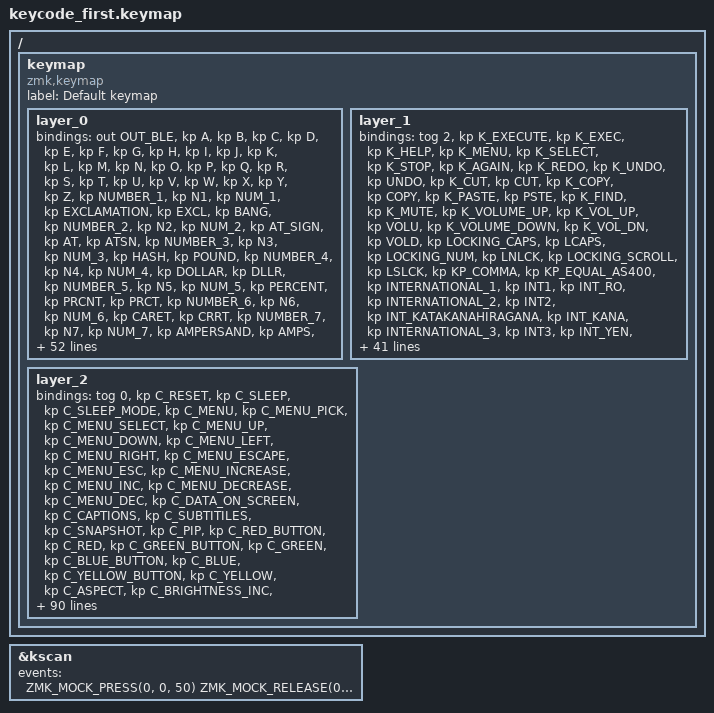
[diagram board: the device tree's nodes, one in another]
#include <dt-bindings/zmk/keys.h>
#include <dt-bindings/zmk/bt.h>
#include <dt-bindings/zmk/outputs.h>
#include <behaviors.dtsi>
#include <dt-bindings/zmk/kscan-mock.h>

/ {
    keymap {
        compatible = "zmk,keymap";
        label = "Default keymap";
        layer_0 {
            bindings = <
                &out OUT_BLE
                &kp A
                &kp B
                &kp C
                &kp D
                &kp E
                &kp F
                &kp G
                &kp H
                &kp I
                &kp J
                &kp K
                &kp L
                &kp M
                &kp N
                &kp O
                &kp P
                &kp Q
                &kp R
                &kp S
                &kp T
                &kp U
                &kp V
                &kp W
                &kp X
                &kp Y
                &kp Z
                &kp NUMBER_1
                &kp N1
                &kp NUM_1
                &kp EXCLAMATION
                &kp EXCL
                &kp BANG
                &kp NUMBER_2
                &kp N2
                &kp NUM_2
                &kp AT_SIGN
                &kp AT
                &kp ATSN
                &kp NUMBER_3
                &kp N3
                &kp NUM_3
                &kp HASH
                &kp POUND
                &kp NUMBER_4
                &kp N4
                &kp NUM_4
                &kp DOLLAR
                &kp DLLR
                &kp NUMBER_5
                &kp N5
                &kp NUM_5
                &kp PERCENT
                &kp PRCNT
                &kp PRCT
                &kp NUMBER_6
                &kp N6
                &kp NUM_6
                &kp CARET
                &kp CRRT
                &kp NUMBER_7
                &kp N7
                &kp NUM_7
                &kp AMPERSAND
                &kp AMPS
                &kp NUMBER_8
                &kp N8
                &kp NUM_8
                &kp ASTERISK
                &kp ASTRK
                &kp STAR
                &kp NUMBER_9
                &kp N9
                &kp NUM_9
                &kp LEFT_PARENTHESIS
                &kp LPAR
                &kp LPRN
                &kp NUMBER_0
                &kp N0
                &kp NUM_0
                &kp RIGHT_PARENTHESIS
                &kp RPAR
                &kp RPRN
                &kp RETURN
                &kp ENTER
                &kp RET
                &kp ESCAPE
                &kp ESC
                &kp BACKSPACE
                &kp BSPC
                &kp BKSP
                &kp TAB
                &kp SPACE
                &kp SPC
                &kp MINUS
                &kp UNDERSCORE
                &kp UNDER
                &kp EQUAL
                &kp EQL
                &kp PLUS
                &kp LEFT_BRACKET
                &kp LBKT
                &kp LEFT_BRACE
                &kp LBRC
                &kp LCUR
                &kp RIGHT_BRACKET
                &kp RBKT
                &kp RIGHT_BRACE
                &kp RBRC
                &kp RCUR
                &kp BACKSLASH
                &kp BSLH
                &kp PIPE
                &kp NON_US_HASH
                &kp TILDE2
                &kp SEMICOLON
                &kp SEMI
                &kp SCLN
                &kp COLON
                &kp COLN
                &kp SINGLE_QUOTE
                &kp SQT
                &kp APOSTROPHE
                &kp APOS
                &kp QUOT
                &kp DOUBLE_QUOTES
                &kp DQT
                &kp GRAVE
                &kp GRAV
                &kp TILDE
                &kp TILD
                &kp COMMA
                &kp CMMA
                &kp LESS_THAN
                &kp LT
                &kp LABT
                &kp PERIOD
                &kp DOT
                &kp GREATER_THAN
                &kp GT
                &kp RABT
                &kp SLASH
                &kp FSLH
                &kp QUESTION
                &kp QMARK
                &kp CAPSLOCK
                &kp CAPS
                &kp CLCK
                &kp F1
                &kp F2
                &kp F3
                &kp F4
                &kp F5
                &kp F6
                &kp F7
                &kp F8
                &kp F9
                &kp F10
                &kp F11
                &kp F12
                &kp PRINTSCREEN
                &kp PSCRN
                &kp PRSC
                &kp SCROLLLOCK
                &kp SLCK
                &kp SCLK
                &kp PAUSE_BREAK
                &kp PAUS
                &kp INSERT
                &kp INS
                &kp HOME
                &kp PAGE_UP
                &kp PG_UP
                &kp PGUP
                &kp DELETE
                &kp DEL
                &kp END
                &kp PAGE_DOWN
                &kp PG_DN
                &kp PGDN
                &kp RIGHT_ARROW
                &kp RIGHT
                &kp RARW
                &kp LEFT_ARROW
                &kp LEFT
                &kp LARW
                &kp DOWN_ARROW
                &kp DOWN
                &kp DARW
                &kp UP_ARROW
                &kp UP
                &kp UARW
                &kp KP_NUMLOCK
                &kp KP_NUM
                &kp KP_NLCK
                &kp CLEAR2
                &kp KP_DIVIDE
                &kp KP_SLASH
                &kp KDIV
                &kp KP_MULTIPLY
                &kp KP_ASTERISK
                &kp KMLT
                &kp KP_MINUS
                &kp KP_SUBTRACT
                &kp KMIN
                &kp KP_PLUS
                &kp KPLS
                &kp KP_ENTER
                &kp KP_NUMBER_1
                &kp KP_N1
                &kp KP_NUMBER_2
                &kp KP_N2
                &kp KP_NUMBER_3
                &kp KP_N3
                &kp KP_NUMBER_4
                &kp KP_N4
                &kp KP_NUMBER_5
                &kp KP_N5
                &kp KP_NUMBER_6
                &kp KP_N6
                &kp KP_NUMBER_7
                &kp KP_N7
                &kp KP_NUMBER_8
                &kp KP_N8
                &kp KP_NUMBER_9
                &kp KP_N9
                &kp KP_NUMBER_0
                &kp KP_N0
                &kp KP_DOT
                &kp NON_US_BACKSLASH
                &kp NON_US_BSLH
                &kp PIPE2
                &kp K_APPLICATION
                &kp K_POWER
                &kp K_APP
                &kp K_CONTEXT_MENU
                &kp K_CMENU
                &kp GUI
                &kp KP_EQUAL
                &kp F13
                &kp F14
                &kp F15
                &kp F16
                &kp F17
                &kp F18
                &kp F19
                &kp F20
                &kp F21
                &kp F22
                &kp F23
                &kp F24
            >;
        };
        layer_1 {
            bindings = <
                &tog 2
                &kp K_EXECUTE
                &kp K_EXEC
                &kp K_HELP
                &kp K_MENU
                &kp K_SELECT
                &kp K_STOP
                &kp K_AGAIN
                &kp K_REDO
                &kp K_UNDO
                &kp UNDO
                &kp K_CUT
                &kp CUT
                &kp K_COPY
                &kp COPY
                &kp K_PASTE
                &kp PSTE
                &kp K_FIND
                &kp K_MUTE
                &kp K_VOLUME_UP
                &kp K_VOL_UP
                &kp VOLU
                &kp K_VOLUME_DOWN
                &kp K_VOL_DN
                &kp VOLD
                &kp LOCKING_CAPS
                &kp LCAPS
                &kp LOCKING_NUM
                &kp LNLCK
                &kp LOCKING_SCROLL
                &kp LSLCK
                &kp KP_COMMA
                &kp KP_EQUAL_AS400
                &kp INTERNATIONAL_1
                &kp INT1
                &kp INT_RO
                &kp INTERNATIONAL_2
                &kp INT2
                &kp INT_KATAKANAHIRAGANA
                &kp INT_KANA
                &kp INTERNATIONAL_3
                &kp INT3
                &kp INT_YEN
                &kp INTERNATIONAL_4
                &kp INT4
                &kp INT_HENKAN
                &kp INTERNATIONAL_5
                &kp INT5
                &kp INT_MUHENKAN
                &kp INTERNATIONAL_6
                &kp INT6
                &kp INT_KPJPCOMMA
                &kp INTERNATIONAL_7
                &kp INT7
                &kp INTERNATIONAL_8
                &kp INT8
                &kp INTERNATIONAL_9
                &kp INT9
                &kp LANGUAGE_1
                &kp LANG1
                &kp LANG_HANGEUL
                &kp LANGUAGE_2
                &kp LANG2
                &kp LANG_HANJA
                &kp LANGUAGE_3
                &kp LANG3
                &kp LANG_KATAKANA
                &kp LANGUAGE_4
                &kp LANG4
                &kp LANG_HIRAGANA
                &kp LANGUAGE_5
                &kp LANG5
                &kp LANG_ZENKAKUHANKAKU
                &kp LANGUAGE_6
                &kp LANG6
                &kp LANGUAGE_7
                &kp LANG7
                &kp LANGUAGE_8
                &kp LANG8
                &kp LANGUAGE_9
                &kp LANG9
                &kp ALT_ERASE
                &kp SYSREQ
                &kp ATTENTION
                &kp K_CANCEL
                &kp CLEAR
                &kp PRIOR
                &kp RETURN2
                &kp RET2
                &kp SEPARATOR
                &kp OUT
                &kp OPER
                &kp CLEAR_AGAIN
                &kp CRSEL
                &kp EXSEL
                &kp CURU
                &kp KP_LEFT_PARENTHESIS
                &kp KP_LPAR
                &kp KP_RIGHT_PARENTHESIS
                &kp KP_RPAR
                &kp KSPC
                &kp KP_CLEAR
                &kp LEFT_CONTROL
                &kp LCTRL
                &kp LCTL
                &kp LEFT_SHIFT
                &kp LSHFT
                &kp LSFT
                &kp LEFT_ALT
                &kp LALT
                &kp LEFT_GUI
                &kp LGUI
                &kp LEFT_WIN
                &kp LWIN
                &kp LEFT_COMMAND
                &kp LCMD
                &kp LEFT_META
                &kp LMETA
                &kp RIGHT_CONTROL
                &kp RCTRL
                &kp RCTL
                &kp RIGHT_SHIFT
                &kp RSHFT
                &kp RSFT
                &kp RIGHT_ALT
                &kp RALT
                &kp RIGHT_GUI
                &kp RGUI
                &kp RIGHT_WIN
                &kp RWIN
                &kp RIGHT_COMMAND
                &kp RCMD
                &kp RIGHT_META
                &kp RMETA
                &kp K_PLAY_PAUSE
                &kp K_PP
                &kp K_STOP2
                &kp K_PREVIOUS
                &kp K_PREV
                &kp K_NEXT
                &kp K_EJECT
                &kp K_VOLUME_UP2
                &kp K_VOL_UP2
                &kp K_VOLUME_DOWN2
                &kp K_VOL_DN2
                &kp K_MUTE2
                &kp K_WWW
                &kp K_BACK
                &kp K_FORWARD
                &kp K_STOP3
                &kp K_FIND2
                &kp K_SCROLL_UP
                &kp K_SCROLL_DOWN
                &kp K_EDIT
                &kp K_SLEEP
                &kp K_LOCK
                &kp K_SCREENSAVER
                &kp K_COFFEE
                &kp K_REFRESH
                &kp K_CALCULATOR
                &kp K_CALC
            >;
        };
        layer_2 {
            bindings = <
                &tog 0
                &kp C_RESET
                &kp C_SLEEP
                &kp C_SLEEP_MODE
                &kp C_MENU
                &kp C_MENU_PICK
                &kp C_MENU_SELECT
                &kp C_MENU_UP
                &kp C_MENU_DOWN
                &kp C_MENU_LEFT
                &kp C_MENU_RIGHT
                &kp C_MENU_ESCAPE
                &kp C_MENU_ESC
                &kp C_MENU_INCREASE
                &kp C_MENU_INC
                &kp C_MENU_DECREASE
                &kp C_MENU_DEC
                &kp C_DATA_ON_SCREEN
                &kp C_CAPTIONS
                &kp C_SUBTITILES
                &kp C_SNAPSHOT
                &kp C_PIP
                &kp C_RED_BUTTON
                &kp C_RED
                &kp C_GREEN_BUTTON
                &kp C_GREEN
                &kp C_BLUE_BUTTON
                &kp C_BLUE
                &kp C_YELLOW_BUTTON
                &kp C_YELLOW
                &kp C_ASPECT
                &kp C_BRIGHTNESS_INC
                &kp C_BRI_INC
                &kp C_BRI_UP
                &kp C_BRIGHTNESS_DEC
                &kp C_BRI_DEC
                &kp C_BRI_DN
                &kp C_BACKLIGHT_TOGGLE
                &kp C_BKLT_TOG
                &kp C_BRIGHTNESS_MINIMUM
                &kp C_BRI_MIN
                &kp C_BRIGHTNESS_MAXIMUM
                &kp C_BRI_MAX
                &kp C_BRIGHTNESS_AUTO
                &kp C_BRI_AUTO
                &kp C_MEDIA_STEP
                &kp C_MODE_STEP
                &kp C_RECALL_LAST
                &kp C_CHAN_LAST
                &kp C_MEDIA_COMPUTER
                &kp C_MEDIA_TV
                &kp C_MEDIA_WWW
                &kp C_MEDIA_DVD
                &kp C_MEDIA_PHONE
                &kp C_MEDIA_GUIDE
                &kp C_MEDIA_VIDEOPHONE
                &kp C_MEDIA_GAMES
                &kp C_MEDIA_MESSAGES
                &kp C_MEDIA_CD
                &kp C_MEDIA_VCR
                &kp C_MEDIA_TUNER
                &kp C_QUIT
                &kp C_HELP
                &kp C_MEDIA_TAPE
                &kp C_MEDIA_CABLE
                &kp C_MEDIA_SATELLITE
                &kp C_MEDIA_HOME
                &kp C_CHANNEL_INC
                &kp C_CHAN_INC
                &kp C_CHANNEL_DEC
                &kp C_CHAN_DEC
                &kp C_MEDIA_VCR_PLUS
                &kp C_PLAY
                &kp C_PAUSE
                &kp C_RECORD
                &kp C_REC
                &kp C_FAST_FORWARD
                &kp C_FF
                &kp C_REWIND
                &kp C_RW
                &kp C_NEXT
                &kp M_NEXT
                &kp C_PREVIOUS
                &kp C_PREV
                &kp M_PREV
                &kp C_STOP
                &kp M_STOP
                &kp C_EJECT
                &kp M_EJCT
                &kp C_RANDOM_PLAY
                &kp C_SHUFFLE
                &kp C_REPEAT
                &kp C_SLOW_TRACKING
                &kp C_SLOW2
                &kp C_STOP_EJECT
                &kp C_PLAY_PAUSE
                &kp C_PP
                &kp M_PLAY
                &kp C_VOICE_COMMAND
                &kp C_MUTE
                &kp M_MUTE
                &kp C_BASS_BOOST
                &kp C_VOLUME_UP
                &kp C_VOL_UP
                &kp M_VOLU
                &kp C_VOLUME_DOWN
                &kp C_VOL_DN
                &kp M_VOLD
                &kp C_SLOW
                &kp C_ALTERNATE_AUDIO_INCREMENT
                &kp C_ALT_AUDIO_INC
                &kp C_AL_CCC
                &kp C_AL_WORD
                &kp C_AL_TEXT_EDITOR
                &kp C_AL_SPREADSHEET
                &kp C_AL_SHEET
                &kp C_AL_GRAPHICS_EDITOR
                &kp C_AL_PRESENTATION
                &kp C_AL_DATABASE
                &kp C_AL_DB
                &kp C_AL_EMAIL
                &kp C_AL_MAIL
                &kp C_AL_NEWS
                &kp C_AL_VOICEMAIL
                &kp C_AL_CONTACTS
                &kp C_AL_ADDRESS_BOOK
                &kp C_AL_CALENDAR
                &kp C_AL_CAL
                &kp C_AL_TASK_MANAGER
                &kp C_AL_JOURNAL
                &kp C_AL_FINANCE
                &kp C_AL_CALCULATOR
                &kp C_AL_CALC
                &kp C_AL_AV_CAPTURE_PLAYBACK
                &kp C_AL_MY_COMPUTER
                &kp C_AL_WWW
                &kp C_AL_NETWORK_CHAT
                &kp C_AL_CHAT
                &kp C_AL_LOGOFF
                &kp C_AL_LOCK
                &kp C_AL_SCREENSAVER
                &kp C_AL_COFFEE
                &kp C_AL_CONTROL_PANEL
                &kp C_AL_SELECT_TASK
                &kp C_AL_NEXT_TASK
                &kp C_AL_PREVIOUS_TASK
                &kp C_AL_PREV_TASK
                &kp C_AL_HELP
                &kp C_AL_DOCUMENTS
                &kp C_AL_DOCS
                &kp C_AL_SPELLCHECK
                &kp C_AL_SPELL
                &kp C_AL_KEYBOARD_LAYOUT
                &kp C_AL_SCREEN_SAVER
                &kp C_AL_FILE_BROWSER
                &kp C_AL_FILES
                &kp C_AL_IMAGE_BROWSER
                &kp C_AL_IMAGES
                &kp C_AL_AUDIO_BROWSER
                &kp C_AL_AUDIO
                &kp C_AL_MUSIC
                &kp C_AL_MOVIE_BROWSER
                &kp C_AL_MOVIES
                &kp C_AL_INSTANT_MESSAGING
                &kp C_AL_IM
                &kp C_AL_OEM_FEATURES
                &kp C_AL_TIPS
                &kp C_AL_TUTORIAL
                &kp C_AC_NEW
                &kp C_AC_OPEN
                &kp C_AC_CLOSE
                &kp C_AC_EXIT
                &kp C_AC_SAVE
                &kp C_AC_PRINT
                &kp C_AC_PROPERTIES
                &kp C_AC_PROPS
                &kp C_AC_UNDO
                &kp C_AC_COPY
                &kp C_AC_CUT
                &kp C_AC_PASTE
                &kp C_AC_FIND
                &kp C_AC_SEARCH
                &kp C_AC_GOTO
                &kp C_AC_HOME
                &kp C_AC_BACK
                &kp C_AC_FORWARD
                &kp C_AC_STOP
                &kp C_AC_REFRESH
                &kp C_AC_BOOKMARKS
                &kp C_AC_FAVORITES
                &kp C_AC_FAVOURITES
                &kp C_AC_ZOOM_IN
                &kp C_AC_ZOOM_OUT
                &kp C_AC_ZOOM
                &kp C_AC_VIEW_TOGGLE
                &kp C_AC_SCROLL_UP
                &kp C_AC_SCROLL_DOWN
                &kp C_AC_EDIT
                &kp C_AC_CANCEL
                &kp C_AC_INSERT
                &kp C_AC_INS
                &kp C_AC_DEL
                &kp C_AC_REDO
                &kp C_AC_REPLY
                &kp C_AC_FORWARD_MAIL
                &kp C_AC_SEND
                &kp C_AC_DESKTOP_SHOW_ALL_WINDOWS
                &kp C_KEYBOARD_INPUT_ASSIST_PREVIOUS
                &kp C_KBIA_PREV
                &kp C_KEYBOARD_INPUT_ASSIST_NEXT
                &kp C_KBIA_NEXT
                &kp C_KEYBOARD_INPUT_ASSIST_PREVIOUS_GROUP
                &kp C_KBIA_PREV_GRP
                &kp C_KEYBOARD_INPUT_ASSIST_NEXT_GROUP
                &kp C_KBIA_NEXT_GRP
                &kp C_KEYBOARD_INPUT_ASSIST_ACCEPT
                &kp C_KBIA_ACCEPT
                &kp C_KEYBOARD_INPUT_ASSIST_CANCEL
                &kp C_KBIA_CANCEL
            >;
        };
    };
};

&kscan {
    events = < 
        ZMK_MOCK_PRESS(0, 0, 50)
        ZMK_MOCK_RELEASE(0, 0, 10000)
        ZMK_MOCK_PRESS(1, 0, 50)
        ZMK_MOCK_RELEASE(1, 0, 100)
        ZMK_MOCK_PRESS(1, 0, 50)
        ZMK_MOCK_RELEASE(1, 0, 100)
        ZMK_MOCK_PRESS(2, 0, 50)
        ZMK_MOCK_RELEASE(2, 0, 100)
        ZMK_MOCK_PRESS(3, 0, 50)
        ZMK_MOCK_RELEASE(3, 0, 100)
        ZMK_MOCK_PRESS(4, 0, 50)
        ZMK_MOCK_RELEASE(4, 0, 100)
        ZMK_MOCK_PRESS(5, 0, 50)
        ZMK_MOCK_RELEASE(5, 0, 100)
        ZMK_MOCK_PRESS(6, 0, 50)
        ZMK_MOCK_RELEASE(6, 0, 100)
        ZMK_MOCK_PRESS(7, 0, 50)
        ZMK_MOCK_RELEASE(7, 0, 100)
        ZMK_MOCK_PRESS(8, 0, 50)
        ZMK_MOCK_RELEASE(8, 0, 100)
        ZMK_MOCK_PRESS(9, 0, 50)
        ZMK_MOCK_RELEASE(9, 0, 100)
        ZMK_MOCK_PRESS(10, 0, 50)
        ZMK_MOCK_RELEASE(10, 0, 100)
        ZMK_MOCK_PRESS(11, 0, 50)
        ZMK_MOCK_RELEASE(11, 0, 100)
        ZMK_MOCK_PRESS(12, 0, 50)
        ZMK_MOCK_RELEASE(12, 0, 100)
        ZMK_MOCK_PRESS(13, 0, 50)
        ZMK_MOCK_RELEASE(13, 0, 100)
        ZMK_MOCK_PRESS(14, 0, 50)
        ZMK_MOCK_RELEASE(14, 0, 100)
        ZMK_MOCK_PRESS(15, 0, 50)
        ZMK_MOCK_RELEASE(15, 0, 100)
        ZMK_MOCK_PRESS(16, 0, 50)
        ZMK_MOCK_RELEASE(16, 0, 100)
        ZMK_MOCK_PRESS(17, 0, 50)
        ZMK_MOCK_RELEASE(17, 0, 100)
        ZMK_MOCK_PRESS(18, 0, 50)
        ZMK_MOCK_RELEASE(18, 0, 100)
        ZMK_MOCK_PRESS(19, 0, 50)
        ZMK_MOCK_RELEASE(19, 0, 100)
        ZMK_MOCK_PRESS(20, 0, 50)
        ZMK_MOCK_RELEASE(20, 0, 100)
        ZMK_MOCK_PRESS(21, 0, 50)
        ZMK_MOCK_RELEASE(21, 0, 100)
        ZMK_MOCK_PRESS(22, 0, 50)
        ZMK_MOCK_RELEASE(22, 0, 100)
        ZMK_MOCK_PRESS(23, 0, 50)
        ZMK_MOCK_RELEASE(23, 0, 100)
        ZMK_MOCK_PRESS(24, 0, 50)
        ZMK_MOCK_RELEASE(24, 0, 100)
        ZMK_MOCK_PRESS(25, 0, 50)
        ZMK_MOCK_RELEASE(25, 0, 100)
        ZMK_MOCK_PRESS(26, 0, 50)
        ZMK_MOCK_RELEASE(26, 0, 100)
        ZMK_MOCK_PRESS(27, 0, 50)
        ZMK_MOCK_RELEASE(27, 0, 100)
        ZMK_MOCK_PRESS(28, 0, 50)
        ZMK_MOCK_RELEASE(28, 0, 100)
        ZMK_MOCK_PRESS(29, 0, 50)
        ZMK_MOCK_RELEASE(29, 0, 100)
        ZMK_MOCK_PRESS(30, 0, 50)
        ZMK_MOCK_RELEASE(30, 0, 100)
        ZMK_MOCK_PRESS(31, 0, 50)
        ZMK_MOCK_RELEASE(31, 0, 100)
        ZMK_MOCK_PRESS(32, 0, 50)
        ZMK_MOCK_RELEASE(32, 0, 100)
        ZMK_MOCK_PRESS(33, 0, 50)
        ZMK_MOCK_RELEASE(33, 0, 100)
        ZMK_MOCK_PRESS(34, 0, 50)
        ZMK_MOCK_RELEASE(34, 0, 100)
        ZMK_MOCK_PRESS(35, 0, 50)
        ZMK_MOCK_RELEASE(35, 0, 100)
        ZMK_MOCK_PRESS(36, 0, 50)
        ZMK_MOCK_RELEASE(36, 0, 100)
        ZMK_MOCK_PRESS(37, 0, 50)
        ZMK_MOCK_RELEASE(37, 0, 100)
        ZMK_MOCK_PRESS(38, 0, 50)
        ZMK_MOCK_RELEASE(38, 0, 100)
        ZMK_MOCK_PRESS(39, 0, 50)
        ZMK_MOCK_RELEASE(39, 0, 100)
        ZMK_MOCK_PRESS(40, 0, 50)
        ZMK_MOCK_RELEASE(40, 0, 100)
        ZMK_MOCK_PRESS(41, 0, 50)
        ZMK_MOCK_RELEASE(41, 0, 100)
        ZMK_MOCK_PRESS(42, 0, 50)
        ZMK_MOCK_RELEASE(42, 0, 100)
        ZMK_MOCK_PRESS(43, 0, 50)
        ZMK_MOCK_RELEASE(43, 0, 100)
        ZMK_MOCK_PRESS(44, 0, 50)
        ZMK_MOCK_RELEASE(44, 0, 100)
        ZMK_MOCK_PRESS(45, 0, 50)
        ZMK_MOCK_RELEASE(45, 0, 100)
        ZMK_MOCK_PRESS(46, 0, 50)
        ZMK_MOCK_RELEASE(46, 0, 100)
        ZMK_MOCK_PRESS(47, 0, 50)
        ZMK_MOCK_RELEASE(47, 0, 100)
        ZMK_MOCK_PRESS(48, 0, 50)
        ZMK_MOCK_RELEASE(48, 0, 100)
        ZMK_MOCK_PRESS(49, 0, 50)
        ZMK_MOCK_RELEASE(49, 0, 100)
        ZMK_MOCK_PRESS(50, 0, 50)
        ZMK_MOCK_RELEASE(50, 0, 100)
        ZMK_MOCK_PRESS(51, 0, 50)
        ZMK_MOCK_RELEASE(51, 0, 100)
        ZMK_MOCK_PRESS(52, 0, 50)
        ZMK_MOCK_RELEASE(52, 0, 100)
        ZMK_MOCK_PRESS(53, 0, 50)
        ZMK_MOCK_RELEASE(53, 0, 100)
        ZMK_MOCK_PRESS(54, 0, 50)
        ZMK_MOCK_RELEASE(54, 0, 100)
        ZMK_MOCK_PRESS(55, 0, 50)
        ZMK_MOCK_RELEASE(55, 0, 100)
        ZMK_MOCK_PRESS(56, 0, 50)
        ZMK_MOCK_RELEASE(56, 0, 100)
        ZMK_MOCK_PRESS(57, 0, 50)
        ZMK_MOCK_RELEASE(57, 0, 100)
        ZMK_MOCK_PRESS(58, 0, 50)
        ZMK_MOCK_RELEASE(58, 0, 100)
        ZMK_MOCK_PRESS(59, 0, 50)
        ZMK_MOCK_RELEASE(59, 0, 100)
        ZMK_MOCK_PRESS(60, 0, 50)
        ZMK_MOCK_RELEASE(60, 0, 100)
        ZMK_MOCK_PRESS(61, 0, 50)
        ZMK_MOCK_RELEASE(61, 0, 100)
        ZMK_MOCK_PRESS(62, 0, 50)
        ZMK_MOCK_RELEASE(62, 0, 100)
        ZMK_MOCK_PRESS(63, 0, 50)
        ZMK_MOCK_RELEASE(63, 0, 100)
        ZMK_MOCK_PRESS(64, 0, 50)
        ZMK_MOCK_RELEASE(64, 0, 100)
        ZMK_MOCK_PRESS(65, 0, 50)
        ZMK_MOCK_RELEASE(65, 0, 100)
        ZMK_MOCK_PRESS(66, 0, 50)
        ZMK_MOCK_RELEASE(66, 0, 100)
        ZMK_MOCK_PRESS(67, 0, 50)
        ZMK_MOCK_RELEASE(67, 0, 100)
        ZMK_MOCK_PRESS(68, 0, 50)
        ZMK_MOCK_RELEASE(68, 0, 100)
        ZMK_MOCK_PRESS(69, 0, 50)
        ZMK_MOCK_RELEASE(69, 0, 100)
        ZMK_MOCK_PRESS(70, 0, 50)
        ZMK_MOCK_RELEASE(70, 0, 100)
        ZMK_MOCK_PRESS(71, 0, 50)
        ZMK_MOCK_RELEASE(71, 0, 100)
        ZMK_MOCK_PRESS(72, 0, 50)
        ZMK_MOCK_RELEASE(72, 0, 100)
        ZMK_MOCK_PRESS(73, 0, 50)
        ZMK_MOCK_RELEASE(73, 0, 100)
        ZMK_MOCK_PRESS(74, 0, 50)
        ZMK_MOCK_RELEASE(74, 0, 100)
        ZMK_MOCK_PRESS(75, 0, 50)
        ZMK_MOCK_RELEASE(75, 0, 100)
        ZMK_MOCK_PRESS(76, 0, 50)
        ZMK_MOCK_RELEASE(76, 0, 100)
        ZMK_MOCK_PRESS(77, 0, 50)
        ZMK_MOCK_RELEASE(77, 0, 100)
        ZMK_MOCK_PRESS(78, 0, 50)
        ZMK_MOCK_RELEASE(78, 0, 100)
        ZMK_MOCK_PRESS(79, 0, 50)
        ZMK_MOCK_RELEASE(79, 0, 100)
        ZMK_MOCK_PRESS(80, 0, 50)
        ZMK_MOCK_RELEASE(80, 0, 100)
        ZMK_MOCK_PRESS(81, 0, 50)
        ZMK_MOCK_RELEASE(81, 0, 100)
        ZMK_MOCK_PRESS(82, 0, 50)
        ZMK_MOCK_RELEASE(82, 0, 100)
        ZMK_MOCK_PRESS(83, 0, 50)
        ZMK_MOCK_RELEASE(83, 0, 100)
        ZMK_MOCK_PRESS(84, 0, 50)
        ZMK_MOCK_RELEASE(84, 0, 100)
        ZMK_MOCK_PRESS(85, 0, 50)
        ZMK_MOCK_RELEASE(85, 0, 100)
        ZMK_MOCK_PRESS(86, 0, 50)
        ZMK_MOCK_RELEASE(86, 0, 100)
        ZMK_MOCK_PRESS(87, 0, 50)
        ZMK_MOCK_RELEASE(87, 0, 100)
        ZMK_MOCK_PRESS(88, 0, 50)
        ZMK_MOCK_RELEASE(88, 0, 100)
        ZMK_MOCK_PRESS(89, 0, 50)
        ZMK_MOCK_RELEASE(89, 0, 100)
        ZMK_MOCK_PRESS(90, 0, 50)
        ZMK_MOCK_RELEASE(90, 0, 100)
        ZMK_MOCK_PRESS(91, 0, 50)
        ZMK_MOCK_RELEASE(91, 0, 100)
        ZMK_MOCK_PRESS(92, 0, 50)
        ZMK_MOCK_RELEASE(92, 0, 100)
        ZMK_MOCK_PRESS(93, 0, 50)
        ZMK_MOCK_RELEASE(93, 0, 100)
        ZMK_MOCK_PRESS(94, 0, 50)
        ZMK_MOCK_RELEASE(94, 0, 100)
        ZMK_MOCK_PRESS(95, 0, 50)
        ZMK_MOCK_RELEASE(95, 0, 100)
        ZMK_MOCK_PRESS(96, 0, 50)
        ZMK_MOCK_RELEASE(96, 0, 100)
        ZMK_MOCK_PRESS(97, 0, 50)
        ZMK_MOCK_RELEASE(97, 0, 100)
        ZMK_MOCK_PRESS(98, 0, 50)
        ZMK_MOCK_RELEASE(98, 0, 100)
        ZMK_MOCK_PRESS(99, 0, 50)
        ZMK_MOCK_RELEASE(99, 0, 100)
        ZMK_MOCK_PRESS(100, 0, 50)
        ZMK_MOCK_RELEASE(100, 0, 100)
        ZMK_MOCK_PRESS(101, 0, 50)
        ZMK_MOCK_RELEASE(101, 0, 100)
        ZMK_MOCK_PRESS(102, 0, 50)
        ZMK_MOCK_RELEASE(102, 0, 100)
        ZMK_MOCK_PRESS(103, 0, 50)
        ZMK_MOCK_RELEASE(103, 0, 100)
        ZMK_MOCK_PRESS(104, 0, 50)
        ZMK_MOCK_RELEASE(104, 0, 100)
        ZMK_MOCK_PRESS(105, 0, 50)
        ZMK_MOCK_RELEASE(105, 0, 100)
        ZMK_MOCK_PRESS(106, 0, 50)
        ZMK_MOCK_RELEASE(106, 0, 100)
        ZMK_MOCK_PRESS(107, 0, 50)
        ZMK_MOCK_RELEASE(107, 0, 100)
        ZMK_MOCK_PRESS(108, 0, 50)
        ZMK_MOCK_RELEASE(108, 0, 100)
        ZMK_MOCK_PRESS(109, 0, 50)
        ZMK_MOCK_RELEASE(109, 0, 100)
        ZMK_MOCK_PRESS(110, 0, 50)
        ZMK_MOCK_RELEASE(110, 0, 100)
        ZMK_MOCK_PRESS(111, 0, 50)
        ZMK_MOCK_RELEASE(111, 0, 100)
        ZMK_MOCK_PRESS(112, 0, 50)
        ZMK_MOCK_RELEASE(112, 0, 100)
        ZMK_MOCK_PRESS(113, 0, 50)
        ZMK_MOCK_RELEASE(113, 0, 100)
        ZMK_MOCK_PRESS(114, 0, 50)
        ZMK_MOCK_RELEASE(114, 0, 100)
        ZMK_MOCK_PRESS(115, 0, 50)
        ZMK_MOCK_RELEASE(115, 0, 100)
        ZMK_MOCK_PRESS(116, 0, 50)
        ZMK_MOCK_RELEASE(116, 0, 100)
        ZMK_MOCK_PRESS(117, 0, 50)
        ZMK_MOCK_RELEASE(117, 0, 100)
        ZMK_MOCK_PRESS(118, 0, 50)
        ZMK_MOCK_RELEASE(118, 0, 100)
        ZMK_MOCK_PRESS(119, 0, 50)
        ZMK_MOCK_RELEASE(119, 0, 100)
        ZMK_MOCK_PRESS(120, 0, 50)
        ZMK_MOCK_RELEASE(120, 0, 100)
        ZMK_MOCK_PRESS(121, 0, 50)
        ZMK_MOCK_RELEASE(121, 0, 100)
        ZMK_MOCK_PRESS(122, 0, 50)
        ZMK_MOCK_RELEASE(122, 0, 100)
        ZMK_MOCK_PRESS(123, 0, 50)
        ZMK_MOCK_RELEASE(123, 0, 100)
        ZMK_MOCK_PRESS(124, 0, 50)
        ZMK_MOCK_RELEASE(124, 0, 100)
        ZMK_MOCK_PRESS(125, 0, 50)
        ZMK_MOCK_RELEASE(125, 0, 100)
        ZMK_MOCK_PRESS(126, 0, 50)
        ZMK_MOCK_RELEASE(126, 0, 100)
        ZMK_MOCK_PRESS(127, 0, 50)
        ZMK_MOCK_RELEASE(127, 0, 100)
        ZMK_MOCK_PRESS(128, 0, 50)
        ZMK_MOCK_RELEASE(128, 0, 100)
        ZMK_MOCK_PRESS(129, 0, 50)
        ZMK_MOCK_RELEASE(129, 0, 100)
        ZMK_MOCK_PRESS(130, 0, 50)
        ZMK_MOCK_RELEASE(130, 0, 100)
        ZMK_MOCK_PRESS(131, 0, 50)
        ZMK_MOCK_RELEASE(131, 0, 100)
        ZMK_MOCK_PRESS(132, 0, 50)
        ZMK_MOCK_RELEASE(132, 0, 100)
        ZMK_MOCK_PRESS(133, 0, 50)
        ZMK_MOCK_RELEASE(133, 0, 100)
        ZMK_MOCK_PRESS(134, 0, 50)
        ZMK_MOCK_RELEASE(134, 0, 100)
        ZMK_MOCK_PRESS(135, 0, 50)
        ZMK_MOCK_RELEASE(135, 0, 100)
        ZMK_MOCK_PRESS(136, 0, 50)
        ZMK_MOCK_RELEASE(136, 0, 100)
        ZMK_MOCK_PRESS(137, 0, 50)
        ZMK_MOCK_RELEASE(137, 0, 100)
        ZMK_MOCK_PRESS(138, 0, 50)
        ZMK_MOCK_RELEASE(138, 0, 100)
        ZMK_MOCK_PRESS(139, 0, 50)
        ZMK_MOCK_RELEASE(139, 0, 100)
        ZMK_MOCK_PRESS(140, 0, 50)
        ZMK_MOCK_RELEASE(140, 0, 100)
        ZMK_MOCK_PRESS(141, 0, 50)
        ZMK_MOCK_RELEASE(141, 0, 100)
        ZMK_MOCK_PRESS(142, 0, 50)
        ZMK_MOCK_RELEASE(142, 0, 100)
        ZMK_MOCK_PRESS(143, 0, 50)
        ZMK_MOCK_RELEASE(143, 0, 100)
        ZMK_MOCK_PRESS(144, 0, 50)
        ZMK_MOCK_RELEASE(144, 0, 100)
        ZMK_MOCK_PRESS(145, 0, 50)
        ZMK_MOCK_RELEASE(145, 0, 100)
        ZMK_MOCK_PRESS(146, 0, 50)
        ZMK_MOCK_RELEASE(146, 0, 100)
        ZMK_MOCK_PRESS(147, 0, 50)
        ZMK_MOCK_RELEASE(147, 0, 100)
        ZMK_MOCK_PRESS(148, 0, 50)
        ZMK_MOCK_RELEASE(148, 0, 100)
        ZMK_MOCK_PRESS(149, 0, 50)
        ZMK_MOCK_RELEASE(149, 0, 100)
        ZMK_MOCK_PRESS(150, 0, 50)
        ZMK_MOCK_RELEASE(150, 0, 100)
        ZMK_MOCK_PRESS(151, 0, 50)
        ZMK_MOCK_RELEASE(151, 0, 100)
        ZMK_MOCK_PRESS(152, 0, 50)
        ZMK_MOCK_RELEASE(152, 0, 100)
        ZMK_MOCK_PRESS(153, 0, 50)
        ZMK_MOCK_RELEASE(153, 0, 100)
        ZMK_MOCK_PRESS(154, 0, 50)
        ZMK_MOCK_RELEASE(154, 0, 100)
        ZMK_MOCK_PRESS(155, 0, 50)
        ZMK_MOCK_RELEASE(155, 0, 100)
        ZMK_MOCK_PRESS(156, 0, 50)
        ZMK_MOCK_RELEASE(156, 0, 100)
        ZMK_MOCK_PRESS(157, 0, 50)
        ZMK_MOCK_RELEASE(157, 0, 100)
        ZMK_MOCK_PRESS(158, 0, 50)
        ZMK_MOCK_RELEASE(158, 0, 100)
        ZMK_MOCK_PRESS(159, 0, 50)
        ZMK_MOCK_RELEASE(159, 0, 100)
        ZMK_MOCK_PRESS(160, 0, 50)
        ZMK_MOCK_RELEASE(160, 0, 100)
        ZMK_MOCK_PRESS(161, 0, 50)
        ZMK_MOCK_RELEASE(161, 0, 100)
        ZMK_MOCK_PRESS(162, 0, 50)
        ZMK_MOCK_RELEASE(162, 0, 100)
        ZMK_MOCK_PRESS(163, 0, 50)
        ZMK_MOCK_RELEASE(163, 0, 100)
        ZMK_MOCK_PRESS(164, 0, 50)
        ZMK_MOCK_RELEASE(164, 0, 100)
        ZMK_MOCK_PRESS(165, 0, 50)
        ZMK_MOCK_RELEASE(165, 0, 100)
        ZMK_MOCK_PRESS(166, 0, 50)
        ZMK_MOCK_RELEASE(166, 0, 100)
        ZMK_MOCK_PRESS(167, 0, 50)
        ZMK_MOCK_RELEASE(167, 0, 100)
        ZMK_MOCK_PRESS(168, 0, 50)
        ZMK_MOCK_RELEASE(168, 0, 100)
        ZMK_MOCK_PRESS(169, 0, 50)
        ZMK_MOCK_RELEASE(169, 0, 100)
        ZMK_MOCK_PRESS(170, 0, 50)
        ZMK_MOCK_RELEASE(170, 0, 100)
        ZMK_MOCK_PRESS(171, 0, 50)
        ZMK_MOCK_RELEASE(171, 0, 100)
        ZMK_MOCK_PRESS(172, 0, 50)
        ZMK_MOCK_RELEASE(172, 0, 100)
        ZMK_MOCK_PRESS(173, 0, 50)
        ZMK_MOCK_RELEASE(173, 0, 100)
        ZMK_MOCK_PRESS(174, 0, 50)
        ZMK_MOCK_RELEASE(174, 0, 100)
        ZMK_MOCK_PRESS(175, 0, 50)
        ZMK_MOCK_RELEASE(175, 0, 100)
        ZMK_MOCK_PRESS(176, 0, 50)
        ZMK_MOCK_RELEASE(176, 0, 100)
        ZMK_MOCK_PRESS(177, 0, 50)
        ZMK_MOCK_RELEASE(177, 0, 100)
        ZMK_MOCK_PRESS(178, 0, 50)
        ZMK_MOCK_RELEASE(178, 0, 100)
        ZMK_MOCK_PRESS(179, 0, 50)
        ZMK_MOCK_RELEASE(179, 0, 100)
        ZMK_MOCK_PRESS(180, 0, 50)
        ZMK_MOCK_RELEASE(180, 0, 100)
        ZMK_MOCK_PRESS(181, 0, 50)
        ZMK_MOCK_RELEASE(181, 0, 100)
        ZMK_MOCK_PRESS(182, 0, 50)
        ZMK_MOCK_RELEASE(182, 0, 100)
        ZMK_MOCK_PRESS(183, 0, 50)
        ZMK_MOCK_RELEASE(183, 0, 100)
        ZMK_MOCK_PRESS(184, 0, 50)
        ZMK_MOCK_RELEASE(184, 0, 100)
        ZMK_MOCK_PRESS(185, 0, 50)
        ZMK_MOCK_RELEASE(185, 0, 100)
        ZMK_MOCK_PRESS(186, 0, 50)
        ZMK_MOCK_RELEASE(186, 0, 100)
        ZMK_MOCK_PRESS(187, 0, 50)
        ZMK_MOCK_RELEASE(187, 0, 100)
        ZMK_MOCK_PRESS(188, 0, 50)
        ZMK_MOCK_RELEASE(188, 0, 100)
        ZMK_MOCK_PRESS(189, 0, 50)
        ZMK_MOCK_RELEASE(189, 0, 100)
        ZMK_MOCK_PRESS(190, 0, 50)
        ZMK_MOCK_RELEASE(190, 0, 100)
        ZMK_MOCK_PRESS(191, 0, 50)
        ZMK_MOCK_RELEASE(191, 0, 100)
        ZMK_MOCK_PRESS(192, 0, 50)
        ZMK_MOCK_RELEASE(192, 0, 100)
        ZMK_MOCK_PRESS(193, 0, 50)
        ZMK_MOCK_RELEASE(193, 0, 100)
        ZMK_MOCK_PRESS(194, 0, 50)
        ZMK_MOCK_RELEASE(194, 0, 100)
        ZMK_MOCK_PRESS(195, 0, 50)
        ZMK_MOCK_RELEASE(195, 0, 100)
        ZMK_MOCK_PRESS(196, 0, 50)
        ZMK_MOCK_RELEASE(196, 0, 100)
        ZMK_MOCK_PRESS(197, 0, 50)
        ZMK_MOCK_RELEASE(197, 0, 100)
        ZMK_MOCK_PRESS(198, 0, 50)
        ZMK_MOCK_RELEASE(198, 0, 100)
        ZMK_MOCK_PRESS(199, 0, 50)
        ZMK_MOCK_RELEASE(199, 0, 100)
        ZMK_MOCK_PRESS(200, 0, 50)
        ZMK_MOCK_RELEASE(200, 0, 100)
        ZMK_MOCK_PRESS(201, 0, 50)
        ZMK_MOCK_RELEASE(201, 0, 100)
        ZMK_MOCK_PRESS(202, 0, 50)
        ZMK_MOCK_RELEASE(202, 0, 100)
        ZMK_MOCK_PRESS(203, 0, 50)
        ZMK_MOCK_RELEASE(203, 0, 100)
        ZMK_MOCK_PRESS(204, 0, 50)
        ZMK_MOCK_RELEASE(204, 0, 100)
        ZMK_MOCK_PRESS(205, 0, 50)
        ZMK_MOCK_RELEASE(205, 0, 100)
        ZMK_MOCK_PRESS(206, 0, 50)
        ZMK_MOCK_RELEASE(206, 0, 100)
        ZMK_MOCK_PRESS(207, 0, 50)
        ZMK_MOCK_RELEASE(207, 0, 100)
        ZMK_MOCK_PRESS(208, 0, 50)
        ZMK_MOCK_RELEASE(208, 0, 100)
        ZMK_MOCK_PRESS(209, 0, 50)
        ZMK_MOCK_RELEASE(209, 0, 100)
        ZMK_MOCK_PRESS(210, 0, 50)
        ZMK_MOCK_RELEASE(210, 0, 100)
        ZMK_MOCK_PRESS(211, 0, 50)
        ZMK_MOCK_RELEASE(211, 0, 100)
        ZMK_MOCK_PRESS(212, 0, 50)
        ZMK_MOCK_RELEASE(212, 0, 100)
        ZMK_MOCK_PRESS(213, 0, 50)
        ZMK_MOCK_RELEASE(213, 0, 100)
        ZMK_MOCK_PRESS(214, 0, 50)
        ZMK_MOCK_RELEASE(214, 0, 100)
        ZMK_MOCK_PRESS(215, 0, 50)
        ZMK_MOCK_RELEASE(215, 0, 100)
        ZMK_MOCK_PRESS(216, 0, 50)
        ZMK_MOCK_RELEASE(216, 0, 100)
        ZMK_MOCK_PRESS(217, 0, 50)
        ZMK_MOCK_RELEASE(217, 0, 100)
        ZMK_MOCK_PRESS(218, 0, 50)
        ZMK_MOCK_RELEASE(218, 0, 100)
        ZMK_MOCK_PRESS(219, 0, 50)
        ZMK_MOCK_RELEASE(219, 0, 100)
        ZMK_MOCK_PRESS(220, 0, 50)
        ZMK_MOCK_RELEASE(220, 0, 100)
        ZMK_MOCK_PRESS(221, 0, 50)
        ZMK_MOCK_RELEASE(221, 0, 100)
        ZMK_MOCK_PRESS(222, 0, 50)
        ZMK_MOCK_RELEASE(222, 0, 100)
        ZMK_MOCK_PRESS(223, 0, 50)
        ZMK_MOCK_RELEASE(223, 0, 100)
        ZMK_MOCK_PRESS(224, 0, 50)
        ZMK_MOCK_RELEASE(224, 0, 100)
        ZMK_MOCK_PRESS(225, 0, 50)
        ZMK_MOCK_RELEASE(225, 0, 100)
        ZMK_MOCK_PRESS(226, 0, 50)
        ZMK_MOCK_RELEASE(226, 0, 100)
        ZMK_MOCK_PRESS(227, 0, 50)
        ZMK_MOCK_RELEASE(227, 0, 100)
        ZMK_MOCK_PRESS(228, 0, 50)
        ZMK_MOCK_RELEASE(228, 0, 100)
        ZMK_MOCK_PRESS(229, 0, 50)
        ZMK_MOCK_RELEASE(229, 0, 100)
        ZMK_MOCK_PRESS(230, 0, 50)
        ZMK_MOCK_RELEASE(230, 0, 100)
        ZMK_MOCK_PRESS(231, 0, 50)
        ZMK_MOCK_RELEASE(231, 0, 100)
        ZMK_MOCK_PRESS(232, 0, 50)
        ZMK_MOCK_RELEASE(232, 0, 100)
        ZMK_MOCK_PRESS(233, 0, 50)
        ZMK_MOCK_RELEASE(233, 0, 100)
        ZMK_MOCK_PRESS(234, 0, 50)
        ZMK_MOCK_RELEASE(234, 0, 100)
        ZMK_MOCK_PRESS(235, 0, 50)
        ZMK_MOCK_RELEASE(235, 0, 100)
        ZMK_MOCK_PRESS(236, 0, 50)
        ZMK_MOCK_RELEASE(236, 0, 100)
        ZMK_MOCK_PRESS(237, 0, 50)
        ZMK_MOCK_RELEASE(237, 0, 100)
        ZMK_MOCK_PRESS(238, 0, 50)
        ZMK_MOCK_RELEASE(238, 0, 100)
        ZMK_MOCK_PRESS(239, 0, 50)
        ZMK_MOCK_RELEASE(239, 0, 100)
        ZMK_MOCK_PRESS(240, 0, 50)
        ZMK_MOCK_RELEASE(240, 0, 100)
        ZMK_MOCK_PRESS(241, 0, 50)
        ZMK_MOCK_RELEASE(241, 0, 100)
        ZMK_MOCK_PRESS(242, 0, 50)
        ZMK_MOCK_RELEASE(242, 0, 100)
        ZMK_MOCK_PRESS(243, 0, 50)
        ZMK_MOCK_RELEASE(243, 0, 100)
        ZMK_MOCK_PRESS(244, 0, 50)
        ZMK_MOCK_RELEASE(244, 0, 100)
        ZMK_MOCK_PRESS(245, 0, 50)
        ZMK_MOCK_RELEASE(245, 0, 100)
        ZMK_MOCK_PRESS(246, 0, 50)
        ZMK_MOCK_RELEASE(246, 0, 100)
        ZMK_MOCK_PRESS(247, 0, 50)
        ZMK_MOCK_RELEASE(247, 0, 100)
        ZMK_MOCK_PRESS(248, 0, 50)
        ZMK_MOCK_RELEASE(248, 0, 100)
        ZMK_MOCK_PRESS(249, 0, 50)
        ZMK_MOCK_RELEASE(249, 0, 100)
        ZMK_MOCK_PRESS(250, 0, 50)
        ZMK_MOCK_RELEASE(250, 0, 100)
        
    >;
};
